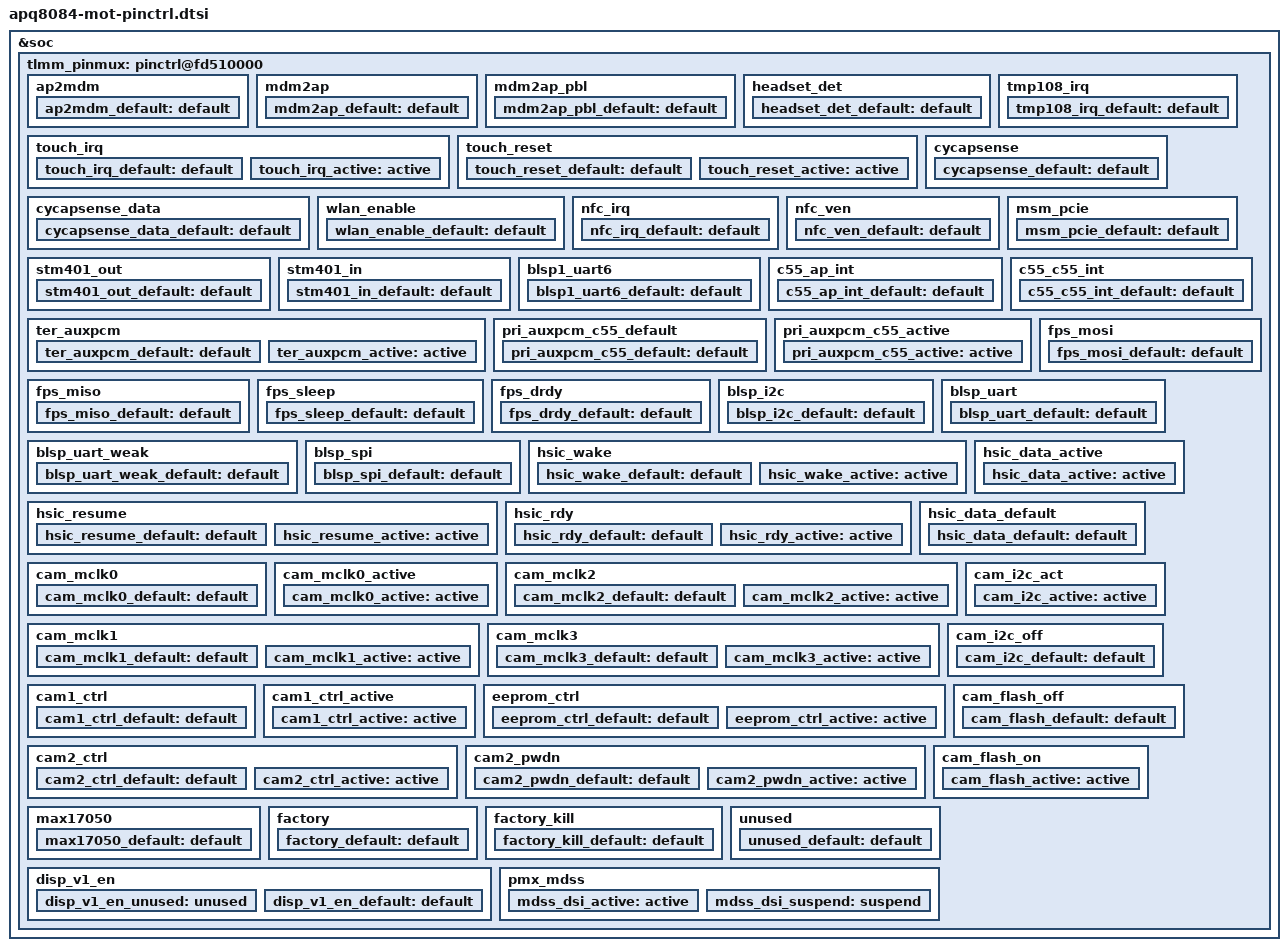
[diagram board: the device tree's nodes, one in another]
/* Copyright (c) 2014, Motorola Mobility. All rights reserved.
 *
 * This program is free software; you can redistribute it and/or modify
 * it under the terms of the GNU General Public License version 2 and
 * only version 2 as published by the Free Software Foundation.
 *
 * This program is distributed in the hope that it will be useful,
 * but WITHOUT ANY WARRANTY; without even the implied warranty of
 * MERCHANTABILITY or FITNESS FOR A PARTICULAR PURPOSE.  See the
 * GNU General Public License for more details.
 */

&soc {
	tlmm_pinmux: pinctrl@fd510000 {

		pinctrl-names = "default";
		pinctrl-0 =	 <
					&ap2mdm_default
					&mdm2ap_default
					&mdm2ap_pbl_default
					&headset_det_default
					&tmp108_irq_default
					&cycapsense_default
					&cycapsense_data_default
					&wlan_enable_default
					&nfc_irq_default
					&nfc_ven_default
					&msm_pcie_default
					&stm401_in_default
					&stm401_out_default
					&blsp1_uart6_default
					&c55_ap_int_default
					&c55_c55_int_default
					&fps_miso_default
					&fps_mosi_default
					&fps_sleep_default
					&fps_drdy_default
					&blsp_i2c_default
					&blsp_uart_default
					&blsp_uart_weak_default
					&blsp_spi_default
					&cam_mclk1_default
					&cam_mclk3_default
					&cam2_pwdn_default
					&max17050_default
					&factory_default
					&factory_kill_default
					&unused_default
					&disp_v1_en_default
					&ter_auxpcm_default
				>;

		/* AP2MDM_STATUS, AP2MDM_ERRFATAL, AP2MDM_SOFTRESET */
		ap2mdm {
			qcom,pins = <&gp 110 &gp 112 &gp 128>;
			qcom,num-grp-pins = <3>;
			qcom,pin-func = <0>;
			label = "ap2mdm";
			ap2mdm_default: default {
				bias-disable;
				drive-strength = <8>;
			};
		};

		/* MDM2AP_STATUS, MDM2AP_ERRFATAL */
		mdm2ap {
			qcom,pins = <&gp 109 &gp 111>;
			qcom,num-grp-pins = <2>;
			qcom,pin-func = <0>;
			label = "mdm2ap";
			mdm2ap_default: default {
				bias-pull-down;
				drive-strength = <8>;
			};
		};

		/* MDM2AP_PBL_READY */
		mdm2ap_pbl {
			qcom,pins = <&gp 113>;
			qcom,num-grp-pins = <1>;
			qcom,pin-func = <0>;
			label = "mdm2ap_pbl";
			mdm2ap_pbl_default: default {
				bias-disable;
				drive-strength = <8>;
			};
		};

		headset_det {
			qcom,pins = <&gp 9>;
			qcom,num-grp-pins = <1>;
			qcom,pin-func = <0>;
			label = "headset_det";
			headset_det_default: default {
				bias-pull-up;
				drive-strength = <2>;
			};
		};

		touch_irq {
			qcom,pins = <&gp 84>;
			qcom,num-grp-pins = <1>;
			qcom,pin-func = <0>;
			label = "touch_irq";
			touch_irq_default: default {
				bias-pull-down;
				drive-strength = <6>;
			};
			touch_irq_active: active {
				bias-pull-up;
				drive-strength = <6>;
			};
		};

		touch_reset {
			qcom,pins = <&gp 97>;
			qcom,num-grp-pins = <1>;
			qcom,pin-func = <0>;
			label = "touch_reset";
			touch_reset_default: default {
				bias-disable;
				output-low;
				drive-strength = <6>;
			};
			touch_reset_active: active {
				bias-pull-up;
				drive-strength = <6>;
			};
		};

		tmp108_irq {
			qcom,pins = <&gp 60>;
			qcom,num-grp-pins = <1>;
			qcom,pin-func = <0>;
			label = "tmp108_irq";
			tmp108_irq_default: default {
				bias-pull-up;
				drive-strength = <2>;
			};
		};

		cycapsense {
			qcom,pins = <&gp 121 &gp 74>;
			qcom,num-grp-pins = <2>;
			qcom,pin-func = <0>;
			label = "cycapsense_";
			cycapsense_default: default {
				bias-disable;
				output-low;
				drive-strength = <2>;
			};
		};

		cycapsense_data {
			qcom,pins = <&gp 73>;
			qcom,num-grp-pins = <1>;
			qcom,pin-func = <0>;
			label = "cycapsense_data";
			cycapsense_data_default: default {
				bias-disable;
				drive-strength = <2>;
			};
		};

		wlan_enable {
			qcom,pins = <&gp 82>;
			qcom,num-grp-pins = <1>;
			qcom,pin-func = <0>;
			label = "wlan_enable";
			wlan_enable_default: default {
				bias-pull-up;
				output-high;
				drive-strength = <16>;
			};
		};

		nfc_irq {
			qcom,pins = <&gp 8>;
			qcom,num-grp-pins = <1>;
			qcom,pin-func = <0>;
			label = "nfc_irq";
			nfc_irq_default: default {
				bias-pull-down;
				drive-strength = <2>;
			};
		};

		nfc_ven {
			qcom,pins = <&gp 116>;
			qcom,num-grp-pins = <1>;
			qcom,pin-func = <0>;
			label = "nfc_ven";
			nfc_ven_default: default {
				bias-pull-down;
				output-low;
				drive-strength = <2>;
			};
		};

		msm_pcie {
			qcom,pins = <&gp 68>;
			qcom,num-grp-pins = <1>;
			qcom,pin-func = <2>;
			label = "msm_pcie";
			msm_pcie_default: default {
				bias-pull-up;
				drive-strength = <2>;
			};
		};

		stm401_out {
			qcom,pins = <&gp 0 &gp 137 &gp 136>;
			qcom,num-grp-pins = <3>;
			qcom,pin-func = <0>;
			label = "stm401_out";
			stm401_out_default: default {
				bias-disable;
				output-low;
				drive-strength = <2>;
			};
		};

		stm401_in {
			qcom,pins = <&gp 1 &gp 122 &gp 141>;
			qcom,num-grp-pins = <3>;
			qcom,pin-func = <0>;
			label = "stm401_in";
			stm401_in_default: default {
				bias-disable;
				drive-strength = <2>;
			};
		};

		blsp1_uart6 {
			qcom,pins = <&gp 43 &gp 44 &gp 45 &gp 46>;
			qcom,num-grp-pins = <4>;
			qcom,pin-func = <2>;
			label = "blsp1_uart6";
			blsp1_uart6_default: default {
				bias-disable;
				drive-strength = <16>;
			};
		};

		/*  used by ti,c55-ctrl */
		c55_ap_int  {
			qcom,pins = <&gp 76>;
			qcom,num-grp-pins = <1>;
			qcom,pin-func = <0>;
			label = "c55_ap_int";
			c55_ap_int_default: default {
				bias-pull-up;
				drive-strength = <2>;
			};
		};

		/*  used by ti,c55-ctrl */
		c55_c55_int  {
			qcom,pins = <&gp 140>;
			qcom,num-grp-pins = <1>;
			qcom,pin-func = <0>;
			label = "c55_c55_int";
			c55_c55_int_default: default {
				bias-disable;
				ouput-high;
				drive-strength = <2>;
			};
		};

		/*  implicilty used by BT module */
		/* move out of hump if BT wants to switch states */
		ter_auxpcm  {
			qcom,pins = <&gp 87 &gp 88 &gp 89 &gp 90>;
			qcom,num-grp-pins = <4>;
			qcom,pin-func = <1>;
			label = "ter_auxpcm";
			ter_auxpcm_default: default {
				bias-pull-down;
				drive-strength = <2>;
			};
			ter_auxpcm_active: active {
				bias-disable;
				drive-strength = <8>;
			};
		};

		/*  used by qcom,apq8084-audio-taiko	*/
		/* do we really have to switch func	*/
		pri_auxpcm_c55_default {
			qcom,pins = <&gp 77 &gp 78 &gp 79 &gp 80>;
			qcom,num-grp-pins = <4>;
			qcom,pin-func = <0>;
			label = "pri_auxpcm_c55_default";
			pri_auxpcm_c55_default: default {
				bias-pull-up;
				drive-strength = <2>;
			};
		};

		/*  used by qcom,apq8084-audio-taiko	*/
		pri_auxpcm_c55_active {
			qcom,pins = <&gp 77 &gp 78 &gp 79 &gp 80>;
			qcom,num-grp-pins = <4>;
			qcom,pin-func = <1>;
			label = "pri_auxpcm_c55_active";
			pri_auxpcm_c55_active: active {
				bias-disable;
				drive-strength = <8>;
			};
		};


		/* finger print sensor spi_sck and spi_mosi */
		fps_mosi  {
			qcom,pins = <&gp 27 &gp 30>;
			qcom,num-grp-pins = <2>;
			qcom,pin-func = <1>;
			label = "fps_mosi";
			fps_mosi_default: default {
				bias-disable;
				drive-strength = <2>;
			};
		};

		/* finger print sensor spi_cs and spi_miso */
		fps_miso  {
			qcom,pins = <&gp 28 &gp 29>;
			qcom,num-grp-pins = <2>;
			qcom,pin-func = <1>;
			label = "fps_miso";
			fps_miso_default: default {
				bias-pull-up;
				drive-strength = <2>;
			};
		};

		/* finger print sensor spi_sleep */
		fps_sleep  {
			qcom,pins = <&gp 127>;
			qcom,num-grp-pins = <1>;
			qcom,pin-func = <0>;
			label = "fps_sleep";
			fps_sleep_default: default {
				bias-pull-up;
				output-high;
				drive-strength = <2>;
			};
		};

		/* finger print sensor spi_sleep */
		fps_drdy  {
			qcom,pins = <&gp 143>;
			qcom,num-grp-pins = <1>;
			qcom,pin-func = <0>;
			label = "fps_drdy";
			fps_drdy_default: default {
				bias-pull-down;
				drive-strength = <2>;
			};
		};

		/* blsp i2c configuration */
		blsp_i2c  {
			qcom,pins = <&gp 10 &gp 11 &gp 41 &gp 42 &gp 49 &gp 50
					&gp 53 &gp 54 &gp 61 &gp 62>;
			qcom,num-grp-pins = <10>;
			qcom,pin-func = <3>;
			label = "blsp_i2c";
			blsp_i2c_default: default {
				bias-disable;
				drive-strength = <2>;
			};
		};

		/* blsp uart configuration */
		blsp_uart  {
			qcom,pins = <&gp 55 &gp 56 &gp 57 &gp 58>;
			qcom,num-grp-pins = <4>;
			qcom,pin-func = <2>;
			label = "blsp_uart";
			blsp_uart_default: default {
				bias-disable;
				drive-strength = <16>;
			};
		};

		/* blsp uart configuration */
		blsp_uart_weak  {
			qcom,pins = <&gp 51 &gp 52>;
			qcom,num-grp-pins = <2>;
			qcom,pin-func = <2>;
			label = "blsp_uart_weak";
			blsp_uart_weak_default: default {
				bias-disable;
				drive-strength = <2>;
			};
		};

		/* blsp spi configuration */
		blsp_spi  {
			qcom,pins = <&gp 3>;
			qcom,num-grp-pins = <1>;
			qcom,pin-func = <1>;
			label = "blsp_spi";
			blsp_spi_default: default {
				bias-disable;
				drive-strength = <6>;
			};
		};

		/* high speed interface qcom,xhci-msm-hsic */
		/* MDM2AP_WAKEUP		           */
		hsic_wake  {
			qcom,pins = <&gp 107>;
			qcom,num-grp-pins = <1>;
			qcom,pin-func = <0>;
			label = "hsic_wake";
			hsic_wake_default: default {
				bias-pull-down;
				drive-strength = <2>;
			};
			hsic_wake_active: active {
				bias-pull-down;
				drive-strength = <8>;
			};
		};

		/* high speed interface qcom,xhci-msm-hsic */
		/* AP2MDM_WAKEUP		           */
		hsic_resume  {
			qcom,pins = <&gp 108>;
			qcom,num-grp-pins = <1>;
			qcom,pin-func = <0>;
			label = "hsic_resume";
			hsic_resume_default: default {
				bias-disable;
				drive-strength = <2>;
			};
			hsic_resume_active: active {
				bias-pull-down;
				output-low;
				drive-strength = <8>;
			};
		};

		/* high speed interface qcom,xhci-msm-hsic */
		/* AP2MDM_CHNL_RDY		           */
		hsic_rdy  {
			qcom,pins = <&gp 106>;
			qcom,num-grp-pins = <1>;
			qcom,pin-func = <0>;
			label = "hsic_rdy";
			hsic_rdy_default: default {
				bias-pull-down;
				output-low;
				drive-strength = <2>;
			};
			hsic_rdy_active: active {
				bias-disable;
				output-low;
				drive-strength = <8>;
			};
		};

		/* high speed interface qcom,xhci-msm-hsic */
		/* HSIC_STROBE and HSIC_DATA active config */
		hsic_data_active  {
			qcom,pins = <&gp 134 &gp 135>;
			qcom,num-grp-pins = <2>;
			qcom,pin-func = <1>;
			label = "hsic_data_active";
			hsic_data_active: active {
				bias-disable;
				drive-strength = <8>;
			};
		};

		/* high speed interface qcom,xhci-msm-hsic */
		/* HSIC_STROBE and HSIC_DATA default config */
		hsic_data_default  {
			qcom,pins = <&gp 134 &gp 135>;
			qcom,num-grp-pins = <2>;
			qcom,pin-func = <0>;
			label = "hsic_data_default";
			hsic_data_default: default {
				bias-pull-down;
				output-low;
				drive-strength = <2>;
			};
		};

		/* camera pinmux settings		*/
		/* CAM_MCLK0				*/
		cam_mclk0 {
			qcom,pins = <&gp 15>;
			qcom,num-grp-pins = <1>;
			label = "cam_mclk0";
			cam_mclk0_default: default {
				bias-pull-down;
				drive-strength = <6>;
			};

		};

		cam_mclk0_active {
			qcom,pins = <&gp 15>;
			qcom,num-grp-pins = <1>;
			qcom,pin-func = <1>;
			label = "cam_mclk0_active";

			cam_mclk0_active: active {
				bias-disable;
				drive-strength = <6>;
			};
		};

		/* camera pinmux settings		*/
		/* CAM_MCLK2				*/
		cam_mclk2 {
			qcom,pins = <&gp 17>;
			qcom,num-grp-pins = <1>;
			qcom,pin-func = <1>;
			label = "cam_mclk2";
			cam_mclk2_default: default {
				bias-pull-down;
				drive-strength = <6>;
			};
			cam_mclk2_active: active {
				bias-disable;
				drive-strength = <6>;
			};
		};

		/* camera pinmux settings		*/
		/* CAM_MCLK1 unused now			*/
		/* leaving them with default state only	*/
		cam_mclk1 {
			qcom,pins = <&gp 16>;
			qcom,num-grp-pins = <1>;
			qcom,pin-func = <1>;
			label = "cam_mclk1";
			cam_mclk1_default: default {
				bias-pull-down;
				drive-strength = <2>;
			};
			cam_mclk1_active: active {
				bias-disable;
				drive-strength = <2>;
			};
		};

		/* camera pinmux settings		*/
		/* CAM_MCLK3 unused now			*/
		/* leaving them with default state only	*/
		cam_mclk3 {
			qcom,pins = <&gp 18>;
			qcom,num-grp-pins = <1>;
			qcom,pin-func = <0>;
			label = "cam_mclk3";
			cam_mclk3_default: default {
				bias-pull-down;
				drive-strength = <2>;
			};
			cam_mclk3_active: active {
				bias-disable;
				drive-strength = <2>;
			};
		};

		/* camera pinmux settings		*/
		/* I2C bus active configuration		*/
		cam_i2c_act {
			qcom,pins = <&gp 19 &gp 20 &gp 21 &gp 22>;
			qcom,num-grp-pins = <4>;
			qcom,pin-func = <1>;
			label = "cam_i2c_act";
			cam_i2c_active: active {
				bias-disable;
				drive-strength = <2>;
			};
		};

		/* camera pinmux settings		*/
		/* I2C bus off configuration		*/
		cam_i2c_off {
			qcom,pins = <&gp 19 &gp 20 &gp 21 &gp 22>;
			qcom,num-grp-pins = <4>;
			qcom,pin-func = <0>;
			label = "cam_i2c_off";
			cam_i2c_default: default {
				bias-disable;
				drive-strength = <2>;
			};
		};

		/* camera pinmux settings		*/
		/* camera 1 reset and stand-by pins	*/
		cam1_ctrl {
			qcom,pins = <&gp 26 &gp 35 &gp 36 &gp 120>;
			qcom,num-grp-pins = <4>;
			label = "cam1_ctrl";
			cam1_ctrl_default: default {
				bias-disable;
				output-low;
				drive-strength = <2>;
			};
		};

		cam1_ctrl_active {
			qcom,pins = <&gp 26 &gp 35 &gp 36 &gp 120>;
			qcom,num-grp-pins = <4>;
			qcom,pin-func = <0>;
			label = "cam1_ctrl_active";

			cam1_ctrl_active: active {
				bias-disable;
				drive-strength = <2>;
			};
		};

		eeprom_ctrl {
			qcom,pins = <&gp 125>;
			qcom,num-grp-pins = <1>;
			qcom,pin-func = <0>;
			label = "eeprom_ctrl";
			eeprom_ctrl_default: default {
				bias-disable;
				output-low;
				drive-strength = <2>;
			};
			eeprom_ctrl_active: active {
				bias-disable;
				drive-strength = <2>;
			};
		};

		/* camera pinmux settings		*/
		/* camera 2 reset and stand-by pins	*/
		cam2_ctrl {
			qcom,pins = <&gp 38 &gp 37>;
			qcom,num-grp-pins = <2>;
			qcom,pin-func = <0>;
			label = "cam2_ctrl";
			cam2_ctrl_default: default {
				bias-disable;
				output-low;
				drive-strength = <2>;
			};
			cam2_ctrl_active: active {
				bias-disable;
				drive-strength = <2>;
			};
		};

		/* camera pinmux settings		*/
		/* camera 2 CAM_R_PWDN_N		*/
		/* not allocated, add to pinctrl hump	*/
		cam2_pwdn {
			qcom,pins = <&gp 25>;
			qcom,num-grp-pins = <1>;
			qcom,pin-func = <0>;
			label = "cam2_pwdn";
			cam2_pwdn_default: default {
				bias-disable;
				output-low;
				drive-strength = <2>;
			};
			cam2_pwdn_active: active {
				bias-disable;
				drive-strength = <2>;
			};
		};

		/* camera pinmux settings		*/
		/* camera flash controls		*/
		cam_flash_off {
			qcom,pins = <&gp 23 &gp 24 &gp 144>;
			qcom,num-grp-pins = <3>;
			qcom,pin-func = <0>;
			label = "cam_flash_off";
			cam_flash_default: default {
				bias-disable;
				output-low;
				drive-strength = <2>;
			};
		};

		/* camera pinmux settings		*/
		/* camera flash controls		*/
		cam_flash_on {
			qcom,pins = <&gp 23 &gp 24 &gp 144>;
			qcom,num-grp-pins = <3>;
			qcom,pin-func = <0>;
			label = "cam_flash_on";
			cam_flash_active: active {
				bias-disable;
				drive-strength = <2>;
			};
		};

		max17050 {
			qcom,pins = <&gp 123>;
			qcom,num-grp-pins = <1>;
			qcom,pin-func = <0>;
			label = "max17050";
			max17050_default: default {
				bias-disable;
				drive-strength = <2>;
			};
		};

		factory {
			qcom,pins = <&gp 34 &gp 146>;
			qcom,num-grp-pins = <2>;
			qcom,pin-func = <0>;
			label = "factory";
			factory_default: default {
				bias-disable;
				drive-strength = <2>;
			};
		};

		factory_kill {
			qcom,pins = <&gp 126>;
			qcom,num-grp-pins = <1>;
			qcom,pin-func = <0>;
			label = "factory_kill";
			factory_kill_default: default {
				bias-disable;
				output-low;
				drive-strength = <2>;
			};
		};

		unused {
			qcom,pins = <&gp 32>;
			qcom,num-grp-pins = <1>;
			qcom,pin-func = <0>;
			label = "unused";
			unused_default: default {
				bias-pull-down;
				drive-strength = <2>;
			};
		};


		/* display regulator enable		*/
		/* gpio used by fixed regulator		*/
		/* do we really need two states for it?	*/
		/* regulator code never frees GPIOS	*/
		disp_v1_en {
			qcom,pins = <&gp 96>;
			qcom,num-grp-pins = <1>;
			qcom,pin-func = <0>;
			label = "disp_v1_en";
			disp_v1_en_unused: unused {
				bias-pull-down;
				drive-strength = <2>;
			};
			disp_v1_en_default: default {
				bias-none;
				output-high;
				drive-strength = <8>;
			};
		};

		pmx_mdss {
			qcom,pins = <&gp 86>;
			qcom,num-grp-pins = <1>;
			qcom,pin-func = <0>;
			label = "mdss-pins";
			mdss_dsi_active: active {
				drive-strength = <8>; /* 8 mA */
				bias-disable = <0>; /* no pull */
				output-high;
			};
			mdss_dsi_suspend: suspend {
				drive-strength = <2>; /* 2 mA */
				bias-pull-down; /* pull down */
				output-low;
			};
		};

	};
};
